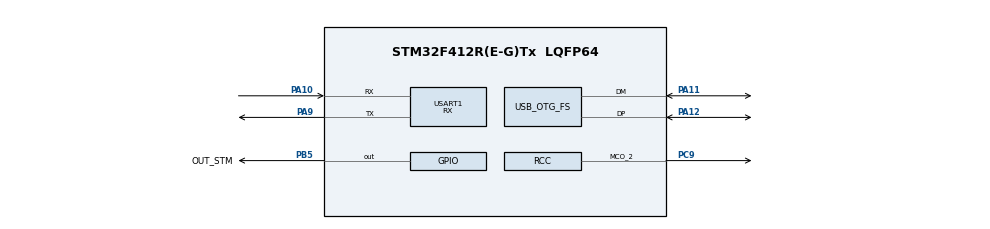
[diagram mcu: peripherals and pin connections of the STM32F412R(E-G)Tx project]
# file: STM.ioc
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Mcu.Family=STM32F4
Mcu.Name=STM32F412R(E-G)Tx
Mcu.Package=LQFP64
NVIC.OTG_FS_IRQn=true\:0\:0\:false\:false\:true\:false\:true\:true
NVIC.PriorityGroup=NVIC_PRIORITYGROUP_4
PA10.Mode=Asynchronous
PA10.Signal=USART1_RX
PA11.Mode=Device_Only
PA11.Signal=USB_OTG_FS_DM
PA12.Mode=Device_Only
PA12.Signal=USB_OTG_FS_DP
PA9.Mode=Asynchronous
PA9.Signal=USART1_TX
PB5.GPIO_Label=OUT_STM
PB5.Signal=GPIO_Output
PC9.Mode=Clock-out-2
PC9.Signal=RCC_MCO_2
PH0\ -\ OSC_IN.Mode=HSE-External-Oscillator
PH0\ -\ OSC_IN.Signal=RCC_OSC_IN
PH1\ -\ OSC_OUT.Mode=HSE-External-Oscillator
PH1\ -\ OSC_OUT.Signal=RCC_OSC_OUT
ProjectManager.HeapSize=0x200
ProjectManager.StackSize=0x400
ProjectManager.TargetToolchain=CMake
RCC.CortexFreq_Value=16000000
RCC.HSE_VALUE=16000000
RCC.PLLM=8
RCC.PLLN=72
RCC.PLLQ=3
RCC.USBFreq_Value=48000000
RCC.VCOOutputFreq_Value=144000000
USART1.Mode=MODE_RX
USART1.StopBits=STOPBITS_2
USART1.VirtualMode=VM_ASYNC
USB_DEVICE.CLASS_NAME_FS=CDC
USB_DEVICE.VirtualMode=Cdc
USB_DEVICE.VirtualModeFS=Cdc_FS
USB_OTG_FS.VirtualMode=Device_Only
VP_USB_DEVICE_VS_USB_DEVICE_CDC_FS.Mode=CDC_FS
board=custom

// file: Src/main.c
/* USER CODE BEGIN Header */
/**
  ******************************************************************************
  * @file           : main.c
  * @brief          : Main program body
  ******************************************************************************
  * @attention
  *
  * Copyright (c) 2025 STMicroelectronics.
  * All rights reserved.
  *
  * This software is licensed under terms that can be found in the LICENSE file
  * in the root directory of this software component.
  * If no LICENSE file comes with this software, it is provided AS-IS.
  *
  ******************************************************************************
  */
/* USER CODE END Header */
#include "main.h"
#include "usart.h"
#include "usb_device.h"
#include "gpio.h"

/* USER CODE BEGIN PV */
// VIDE CODED START
#include "usbd_cdc_if.h"
#include "usart.h"

#define USB_RX_BUF_SIZE   64
#define UART_RX_BUF_SIZE  64

uint8_t usb_rx_buf[USB_RX_BUF_SIZE];
uint8_t uart_rx_buf[UART_RX_BUF_SIZE];

extern UART_HandleTypeDef huart1;
// VIDE CODED END

/* USER CODE END PV */

void SystemClock_Config(void);

int main(void)
{

  /* MCU Configuration--------------------------------------------------------*/

  /* Reset of all peripherals, Initializes the Flash interface and the Systick. */
  HAL_Init();

  /* Configure the system clock */
  SystemClock_Config();

  /* Initialize all configured peripherals */
  MX_GPIO_Init();
  MX_USB_DEVICE_Init();
  MX_USART1_UART_Init();

  /* Infinite loop */
  /* USER CODE BEGIN WHILE */
  while (1)
  {

    HAL_GPIO_TogglePin(OUT_STM_GPIO_Port, OUT_STM_Pin);
    HAL_Delay(100);
    /* USER CODE END WHILE */

  }
}

void SystemClock_Config(void)
{
  RCC_OscInitTypeDef RCC_OscInitStruct = {0};
  RCC_ClkInitTypeDef RCC_ClkInitStruct = {0};

  /** Configure the main internal regulator output voltage
  */
  __HAL_RCC_PWR_CLK_ENABLE();
  __HAL_PWR_VOLTAGESCALING_CONFIG(PWR_REGULATOR_VOLTAGE_SCALE1);

  /** Initializes the RCC Oscillators according to the specified parameters
  * in the RCC_OscInitTypeDef structure.
  */
  RCC_OscInitStruct.OscillatorType = RCC_OSCILLATORTYPE_HSI|RCC_OSCILLATORTYPE_HSE;
  RCC_OscInitStruct.HSEState = RCC_HSE_ON;
  RCC_OscInitStruct.HSIState = RCC_HSI_ON;
  RCC_OscInitStruct.HSICalibrationValue = RCC_HSICALIBRATION_DEFAULT;
  RCC_OscInitStruct.PLL.PLLState = RCC_PLL_ON;
  RCC_OscInitStruct.PLL.PLLSource = RCC_PLLSOURCE_HSE;
  RCC_OscInitStruct.PLL.PLLM = 8;
  RCC_OscInitStruct.PLL.PLLN = 72;
  RCC_OscInitStruct.PLL.PLLP = RCC_PLLP_DIV2;
  RCC_OscInitStruct.PLL.PLLQ = 3;
  RCC_OscInitStruct.PLL.PLLR = 2;
  if (HAL_RCC_OscConfig(&RCC_OscInitStruct) != HAL_OK)
  {
    Error_Handler();
  }

  /** Initializes the CPU, AHB and APB buses clocks
  */
  RCC_ClkInitStruct.ClockType = RCC_CLOCKTYPE_HCLK|RCC_CLOCKTYPE_SYSCLK
                              |RCC_CLOCKTYPE_PCLK1|RCC_CLOCKTYPE_PCLK2;
  RCC_ClkInitStruct.SYSCLKSource = RCC_SYSCLKSOURCE_HSI;
  RCC_ClkInitStruct.AHBCLKDivider = RCC_SYSCLK_DIV1;
  RCC_ClkInitStruct.APB1CLKDivider = RCC_HCLK_DIV1;
  RCC_ClkInitStruct.APB2CLKDivider = RCC_HCLK_DIV1;

  if (HAL_RCC_ClockConfig(&RCC_ClkInitStruct, FLASH_LATENCY_0) != HAL_OK)
  {
    Error_Handler();
  }
  HAL_RCC_MCOConfig(RCC_MCO2, RCC_MCO2SOURCE_SYSCLK, RCC_MCODIV_1);
}

void Error_Handler(void)
{
  __disable_irq();
  while (1)
  {
  }
}
